VERSION ""

NS_ :

BS_:

BU_:

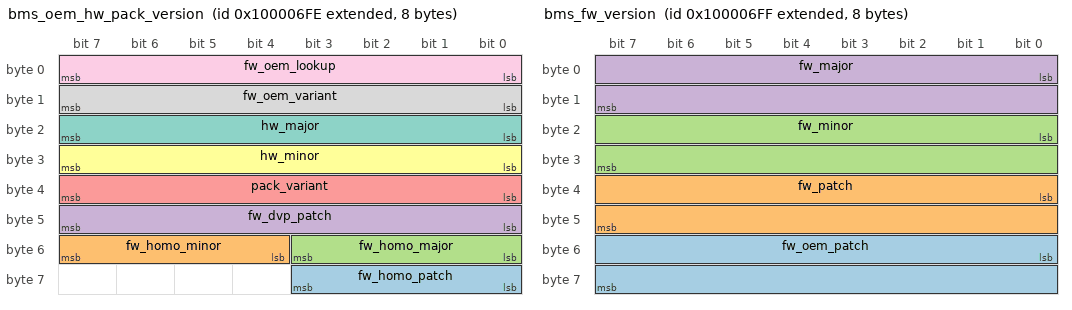
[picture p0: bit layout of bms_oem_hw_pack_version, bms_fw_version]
BO_ 2415920894 bms_oem_hw_pack_version: 8 Vector__XXX
 SG_ fw_homo_patch : 56|4@1+ (1,0) [0|15] "" Vector__XXX
 SG_ fw_homo_minor : 52|4@1+ (1,0) [0|15] "" Vector__XXX
 SG_ fw_homo_major : 48|4@1+ (1,0) [0|15] "" Vector__XXX
 SG_ fw_dvp_patch : 40|8@1+ (1,0) [0|255] "" Vector__XXX
 SG_ pack_variant : 32|8@1+ (1,0) [0|255] "" Vector__XXX
 SG_ hw_minor : 24|8@1+ (1,0) [0|255] "" Vector__XXX
 SG_ hw_major : 16|8@1+ (1,0) [0|255] "" Vector__XXX
 SG_ fw_oem_variant : 8|8@1+ (1,0) [0|255] "" Vector__XXX
 SG_ fw_oem_lookup : 0|8@1+ (1,0) [0|255] "" Vector__XXX

BO_ 2415920895 bms_fw_version: 8 Vector__XXX
 SG_ fw_oem_patch : 48|16@1+ (1,0) [0|65535] "" Vector__XXX
 SG_ fw_patch : 32|16@1+ (1,0) [0|65535] "" Vector__XXX
 SG_ fw_minor : 16|16@1+ (1,0) [0|65535] "" Vector__XXX
 SG_ fw_major : 0|16@1+ (1,0) [0|65535] "" Vector__XXX

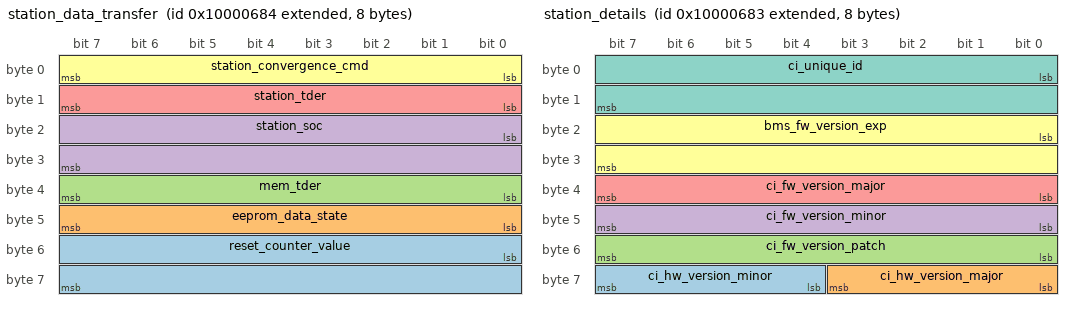
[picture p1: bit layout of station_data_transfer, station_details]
BO_ 2415920772 station_data_transfer: 8 Vector__XXX
 SG_ reset_counter_value : 48|16@1+ (1,0) [0|65535] "" Vector__XXX
 SG_ eeprom_data_state : 40|8@1+ (1,0) [0|255] "" Vector__XXX
 SG_ mem_tder : 32|8@1+ (1,0) [0|255] "" Vector__XXX
 SG_ station_soc : 16|16@1+ (1,0.1) [0.1|65535.1] "" Vector__XXX
 SG_ station_tder : 8|8@1+ (1,0) [0|255] "" Vector__XXX
 SG_ station_convergence_cmd : 0|8@1+ (1,0) [0|255] "" Vector__XXX

BO_ 2415920771 station_details: 8 Vector__XXX
 SG_ ci_hw_version_minor : 60|4@1+ (1,0) [0|15] "" Vector__XXX
 SG_ ci_hw_version_major : 56|4@1+ (1,0) [0|15] "" Vector__XXX
 SG_ ci_fw_version_patch : 48|8@1+ (1,0) [0|255] "" Vector__XXX
 SG_ ci_fw_version_minor : 40|8@1+ (1,0) [0|255] "" Vector__XXX
 SG_ ci_fw_version_major : 32|8@1+ (1,0) [0|255] "" Vector__XXX
 SG_ bms_fw_version_exp : 16|16@1+ (1,0) [0|65535] "" Vector__XXX
 SG_ ci_unique_id : 0|16@1+ (1,0) [0|65535] "" Vector__XXX

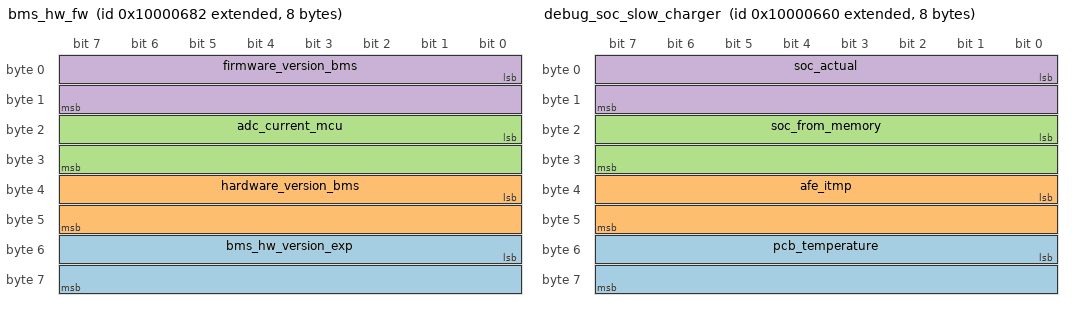
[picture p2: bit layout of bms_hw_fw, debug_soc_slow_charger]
BO_ 2415920770 bms_hw_fw: 8 Vector__XXX
 SG_ bms_hw_version_exp : 48|16@1+ (1,0) [0|65535] "" Vector__XXX
 SG_ hardware_version_bms : 32|16@1+ (1,0) [0|65535] "" Vector__XXX
 SG_ adc_current_mcu : 16|16@1+ (1,0) [0|65535] "" Vector__XXX
 SG_ firmware_version_bms : 0|16@1+ (1,0) [0|65535] "" Vector__XXX

BO_ 2415920769 bms_unique_Key: 8 Vector__XXX
 SG_ bms_unique_key : 0|64@1+ (1,0) [0|18446744073709551615] "" Vector__XXX

BO_ 2415920736 debug_soc_slow_charger: 8 Vector__XXX
 SG_ pcb_temperature : 48|16@1+ (0.01,-100.0) [-100.0|555.35] "" Vector__XXX
 SG_ afe_itmp : 32|16@1+ (0.01,-100.0) [-100.0|555.35] "" Vector__XXX
 SG_ soc_from_memory : 16|16@1+ (1,0) [0|65535] "" Vector__XXX
 SG_ soc_actual : 0|16@1+ (0.01,0.0) [0.0|655.35] "" Vector__XXX

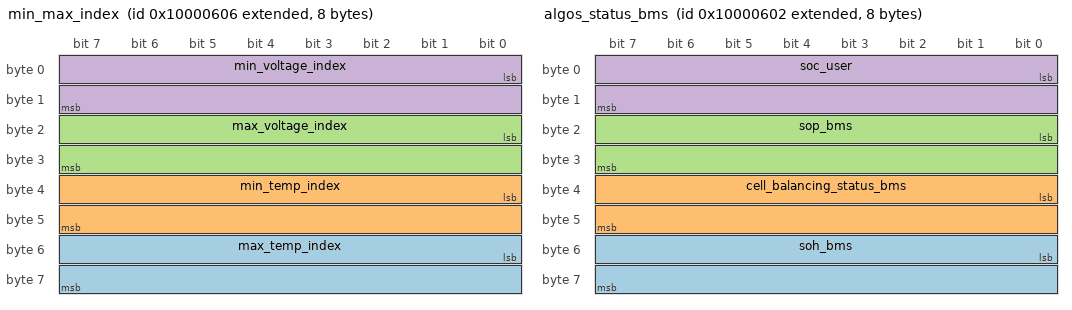
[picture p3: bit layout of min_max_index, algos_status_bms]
BO_ 2415920646 min_max_index: 8 Vector__XXX
 SG_ max_temp_index : 48|16@1+ (1,0) [0|65535] "" Vector__XXX
 SG_ min_temp_index : 32|16@1+ (1,0) [0|65535] "" Vector__XXX
 SG_ max_voltage_index : 16|16@1+ (1,0) [0|65535] "" Vector__XXX
 SG_ min_voltage_index : 0|16@1+ (1,0) [0|65535] "" Vector__XXX

BO_ 2415920647 history_of_protections: 8 Vector__XXX
 SG_ reset_cause : 48|16@1+ (1,0) [0|65535] "" Vector__XXX
 SG_ characterization_cycle_count : 32|16@1+ (0.1,0.0) [0.0|6553.5] "" Vector__XXX
 SG_ idp_bms_hist : 25|1@1+ (1,0) [0|1] "" Vector__XXX
 SG_ rm_bms_hist : 24|1@1+ (1,0) [0|1] "" Vector__XXX
 SG_ doc1_bms_hist : 23|1@1+ (1,0) [0|1] "" Vector__XXX
 SG_ cnot_bms_hist : 22|1@1+ (1,0) [0|1] "" Vector__XXX
 SG_ afe_tp_bms_hist : 21|1@1+ (1,0) [0|1] "" Vector__XXX
 SG_ ib1_bms_hist : 20|1@1+ (1,0) [0|1] "" Vector__XXX
 SG_ ccov_bms_hist : 19|1@1+ (1,0) [0|1] "" Vector__XXX
 SG_ sc_coc1_bms_hist : 18|1@1+ (1,0) [0|1] "" Vector__XXX
 SG_ ccuv_bms_hist : 17|1@1+ (1,0) [0|1] "" Vector__XXX
 SG_ icp_hist : 16|1@1+ (1,0) [0|1] "" Vector__XXX
 SG_ sc_coc_bms_hist : 15|1@1+ (1,0) [0|1] "" Vector__XXX
 SG_ roc_bms_hist : 14|1@1+ (1,0) [0|1] "" Vector__XXX
 SG_ scf_bms_hist : 13|1@1+ (1,0) [0|1] "" Vector__XXX
 SG_ tso_bms_hist : 12|1@1+ (1,0) [0|1] "" Vector__XXX
 SG_ ib_bms_hist : 11|1@1+ (1,0) [0|1] "" Vector__XXX
 SG_ cso_bms_hist : 10|1@1+ (1,0) [0|1] "" Vector__XXX
 SG_ dut_bms_hist : 9|1@1+ (1,0) [0|1] "" Vector__XXX
 SG_ cut_bms_hist : 8|1@1+ (1,0) [0|1] "" Vector__XXX
 SG_ dot_bms_hist : 7|1@1+ (1,0) [0|1] "" Vector__XXX
 SG_ cot_bms_hist : 6|1@1+ (1,0) [0|1] "" Vector__XXX
 SG_ doc_bms_hist : 5|1@1+ (1,0) [0|1] "" Vector__XXX
 SG_ coc_bms_hist : 4|1@1+ (1,0) [0|1] "" Vector__XXX
 SG_ puv_bms_hist : 3|1@1+ (1,0) [0|1] "" Vector__XXX
 SG_ pov_bms_hist : 2|1@1+ (1,0) [0|1] "" Vector__XXX
 SG_ cuv_bms_hist : 1|1@1+ (1,0) [0|1] "" Vector__XXX
 SG_ cov_bms_hist : 0|1@1+ (1,0) [0|1] "" Vector__XXX

BO_ 2415920768 battery_unique_key: 8 Vector__XXX
 SG_ battery_unique_key : 0|64@1+ (1,0) [0|18446744073709551615] "" Vector__XXX

BO_ 2415920642 algos_status_bms: 8 Vector__XXX
 SG_ soh_bms : 48|16@1+ (0.01,0.0) [0.0|655.35] "" Vector__XXX
 SG_ cell_balancing_status_bms : 32|16@1+ (1,0) [0|65535] "" Vector__XXX
 SG_ sop_bms : 16|16@1+ (1,0) [0|65535] "" Vector__XXX
 SG_ soc_user : 0|16@1+ (0.01,0.0) [0.0|655.35] "" Vector__XXX

BO_ 2415920641 safety_status_bms: 8 Vector__XXX
 SG_ idp_flag_bms : 57|1@1+ (1,0) [0|1] "" Vector__XXX
 SG_ rm_flag_bms : 56|1@1+ (1,0) [0|1] "" Vector__XXX
 SG_ doc1_flag_bms : 55|1@1+ (1,0) [0|1] "" Vector__XXX
 SG_ cnot_flag_bms : 54|1@1+ (1,0) [0|1] "" Vector__XXX
 SG_ afe_tp_bms_flag : 53|1@1+ (1,0) [0|1] "" Vector__XXX
 SG_ ib1_bms_flag : 52|1@1+ (1,0) [0|1] "" Vector__XXX
 SG_ ccov_flag_bms : 51|1@1+ (1,0) [0|1] "" Vector__XXX
 SG_ sc_coc1_flag_bms : 50|1@1+ (1,0) [0|1] "" Vector__XXX
 SG_ ccuv_flag_bms : 49|1@1+ (1,0) [0|1] "" Vector__XXX
 SG_ icp_flag : 48|1@1+ (1,0) [0|1] "" Vector__XXX
 SG_ sc_coc_flag_bms : 47|1@1+ (1,0) [0|1] "" Vector__XXX
 SG_ roc_flag_bms : 46|1@1+ (1,0) [0|1] "" Vector__XXX
 SG_ scf_flag_bms : 45|1@1+ (1,0) [0|1] "" Vector__XXX
 SG_ tso_flag_bms : 44|1@1+ (1,0) [0|1] "" Vector__XXX
 SG_ ib_bms_flag : 43|1@1+ (1,0) [0|1] "" Vector__XXX
 SG_ cso_flag_bms : 42|1@1+ (1,0) [0|1] "" Vector__XXX
 SG_ dut_flag_bms : 41|1@1+ (1,0) [0|1] "" Vector__XXX
 SG_ cut_flag_bms : 40|1@1+ (1,0) [0|1] "" Vector__XXX
 SG_ dot_flag_bms : 39|1@1+ (1,0) [0|1] "" Vector__XXX
 SG_ cot_flag_bms : 38|1@1+ (1,0) [0|1] "" Vector__XXX
 SG_ doc_flag_bms : 37|1@1+ (1,0) [0|1] "" Vector__XXX
 SG_ coc_flag_bms : 36|1@1+ (1,0) [0|1] "" Vector__XXX
 SG_ puv_flag_bms : 35|1@1+ (1,0) [0|1] "" Vector__XXX
 SG_ pov_flag_bms : 34|1@1+ (1,0) [0|1] "" Vector__XXX
 SG_ cuv_flag_bms : 33|1@1+ (1,0) [0|1] "" Vector__XXX
 SG_ cov_flag_bms : 32|1@1+ (1,0) [0|1] "" Vector__XXX
 SG_ idp_bms : 25|1@1+ (1,0) [0|1] "" Vector__XXX
 SG_ rm_bms : 24|1@1+ (1,0) [0|1] "" Vector__XXX
 SG_ doc1_bms : 23|1@1+ (1,0) [0|1] "" Vector__XXX
 SG_ cnot_bms : 22|1@1+ (1,0) [0|1] "" Vector__XXX
 SG_ afe_tp_bms : 21|1@1+ (1,0) [0|1] "" Vector__XXX
 SG_ ib1_bms : 20|1@1+ (1,0) [0|1] "" Vector__XXX
 SG_ ccov_bms : 19|1@1+ (1,0) [0|1] "" Vector__XXX
 SG_ sc_coc1_bms : 18|1@1+ (1,0) [0|1] "" Vector__XXX
 SG_ ccuv_bms : 17|1@1+ (1,0) [0|1] "" Vector__XXX
 SG_ icp_status : 16|1@1+ (1,0) [0|1] "" Vector__XXX
 SG_ sc_coc_bms : 15|1@1+ (1,0) [0|1] "" Vector__XXX
 SG_ roc_bms : 14|1@1+ (1,0) [0|1] "" Vector__XXX
 SG_ scf_bms : 13|1@1+ (1,0) [0|1] "" Vector__XXX
 SG_ tso_bms : 12|1@1+ (1,0) [0|1] "" Vector__XXX
 SG_ ib_bms : 11|1@1+ (1,0) [0|1] "" Vector__XXX
 SG_ cso_bms : 10|1@1+ (1,0) [0|1] "" Vector__XXX
 SG_ dut_bms : 9|1@1+ (1,0) [0|1] "" Vector__XXX
 SG_ cut_bms : 8|1@1+ (1,0) [0|1] "" Vector__XXX
 SG_ dot_bms : 7|1@1+ (1,0) [0|1] "" Vector__XXX
 SG_ cot_bms : 6|1@1+ (1,0) [0|1] "" Vector__XXX
 SG_ doc_bms : 5|1@1+ (1,0) [0|1] "" Vector__XXX
 SG_ coc_bms : 4|1@1+ (1,0) [0|1] "" Vector__XXX
 SG_ puv_bms : 3|1@1+ (1,0) [0|1] "" Vector__XXX
 SG_ pov_bms : 2|1@1+ (1,0) [0|1] "" Vector__XXX
 SG_ cuv_bms : 1|1@1+ (1,0) [0|1] "" Vector__XXX
 SG_ cov_bms : 0|1@1+ (1,0) [0|1] "" Vector__XXX

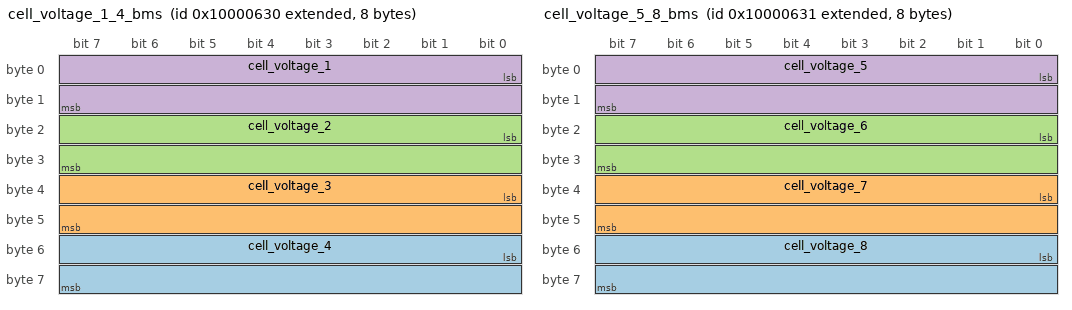
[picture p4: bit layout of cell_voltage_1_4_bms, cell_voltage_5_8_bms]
BO_ 2415920688 cell_voltage_1_4_bms: 8 Vector__XXX
 SG_ cell_voltage_4 : 48|16@1+ (0.0001,0.0) [0.0|6.5535000000000005] "" Vector__XXX
 SG_ cell_voltage_3 : 32|16@1+ (0.0001,0.0) [0.0|6.5535000000000005] "" Vector__XXX
 SG_ cell_voltage_2 : 16|16@1+ (0.0001,0.0) [0.0|6.5535000000000005] "" Vector__XXX
 SG_ cell_voltage_1 : 0|16@1+ (0.0001,0.0) [0.0|6.5535000000000005] "" Vector__XXX

BO_ 2415920689 cell_voltage_5_8_bms: 8 Vector__XXX
 SG_ cell_voltage_8 : 48|16@1+ (0.0001,0.0) [0.0|6.5535000000000005] "" Vector__XXX
 SG_ cell_voltage_7 : 32|16@1+ (0.0001,0.0) [0.0|6.5535000000000005] "" Vector__XXX
 SG_ cell_voltage_6 : 16|16@1+ (0.0001,0.0) [0.0|6.5535000000000005] "" Vector__XXX
 SG_ cell_voltage_5 : 0|16@1+ (0.0001,0.0) [0.0|6.5535000000000005] "" Vector__XXX

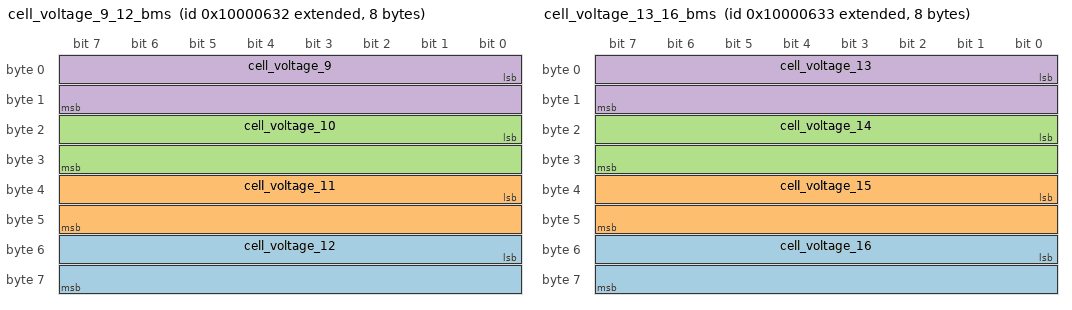
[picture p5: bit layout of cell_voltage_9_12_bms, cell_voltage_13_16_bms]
BO_ 2415920690 cell_voltage_9_12_bms: 8 Vector__XXX
 SG_ cell_voltage_12 : 48|16@1+ (0.0001,0.0) [0.0|6.5535000000000005] "" Vector__XXX
 SG_ cell_voltage_11 : 32|16@1+ (0.0001,0.0) [0.0|6.5535000000000005] "" Vector__XXX
 SG_ cell_voltage_10 : 16|16@1+ (0.0001,0.0) [0.0|6.5535000000000005] "" Vector__XXX
 SG_ cell_voltage_9 : 0|16@1+ (0.0001,0.0) [0.0|6.5535000000000005] "" Vector__XXX

BO_ 2415920691 cell_voltage_13_16_bms: 8 Vector__XXX
 SG_ cell_voltage_16 : 48|16@1+ (0.0001,0.0) [0.0|6.5535000000000005] "" Vector__XXX
 SG_ cell_voltage_15 : 32|16@1+ (0.0001,0.0) [0.0|6.5535000000000005] "" Vector__XXX
 SG_ cell_voltage_14 : 16|16@1+ (0.0001,0.0) [0.0|6.5535000000000005] "" Vector__XXX
 SG_ cell_voltage_13 : 0|16@1+ (0.0001,0.0) [0.0|6.5535000000000005] "" Vector__XXX

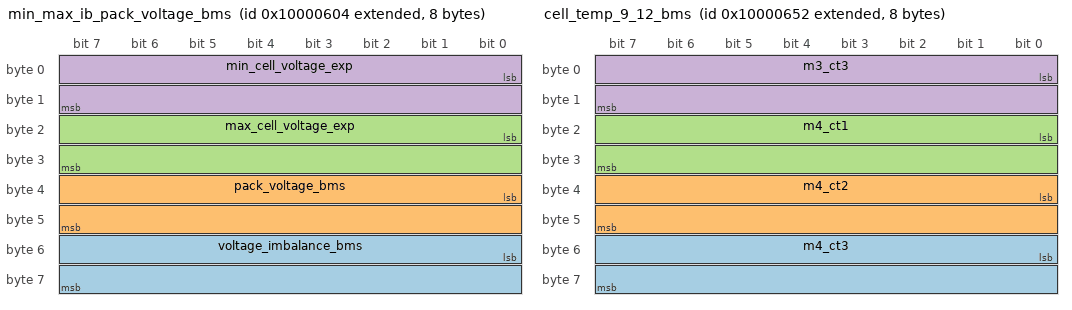
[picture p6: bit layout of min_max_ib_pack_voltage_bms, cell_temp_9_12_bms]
BO_ 2415920644 min_max_ib_pack_voltage_bms: 8 Vector__XXX
 SG_ voltage_imbalance_bms : 48|16@1+ (0.0001,0.0) [0.0|6.5535000000000005] "" Vector__XXX
 SG_ pack_voltage_bms : 32|16@1+ (0.01,0.0) [0.0|655.35] "" Vector__XXX
 SG_ max_cell_voltage_exp : 16|16@1+ (0.0001,0.0) [0.0|6.5535000000000005] "" Vector__XXX
 SG_ min_cell_voltage_exp : 0|16@1+ (0.0001,0.0) [0.0|6.5535000000000005] "" Vector__XXX

BO_ 2415920722 cell_temp_9_12_bms: 8 Vector__XXX
 SG_ m4_ct3 : 48|16@1+ (0.01,-100.0) [-100.0|555.35] "" Vector__XXX
 SG_ m4_ct2 : 32|16@1+ (0.01,-100.0) [-100.0|555.35] "" Vector__XXX
 SG_ m4_ct1 : 16|16@1+ (0.01,-100.0) [-100.0|555.35] "" Vector__XXX
 SG_ m3_ct3 : 0|16@1+ (0.01,-100.0) [-100.0|555.35] "" Vector__XXX

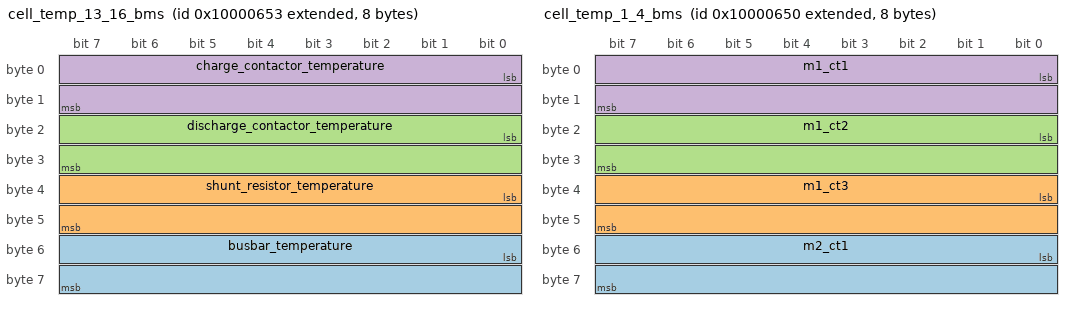
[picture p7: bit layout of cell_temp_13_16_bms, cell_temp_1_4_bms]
BO_ 2415920723 cell_temp_13_16_bms: 8 Vector__XXX
 SG_ busbar_temperature : 48|16@1+ (0.01,-100.0) [-100.0|555.35] "" Vector__XXX
 SG_ shunt_resistor_temperature : 32|16@1+ (0.01,-100.0) [-100.0|555.35] "" Vector__XXX
 SG_ discharge_contactor_temperature : 16|16@1+ (0.01,-100.0) [-100.0|555.35] "" Vector__XXX
 SG_ charge_contactor_temperature : 0|16@1+ (0.01,-100.0) [-100.0|555.35] "" Vector__XXX

BO_ 2415920720 cell_temp_1_4_bms: 8 Vector__XXX
 SG_ m2_ct1 : 48|16@1+ (0.01,-100.0) [-100.0|555.35] "" Vector__XXX
 SG_ m1_ct3 : 32|16@1+ (0.01,-100.0) [-100.0|555.35] "" Vector__XXX
 SG_ m1_ct2 : 16|16@1+ (0.01,-100.0) [-100.0|555.35] "" Vector__XXX
 SG_ m1_ct1 : 0|16@1+ (0.01,-100.0) [-100.0|555.35] "" Vector__XXX

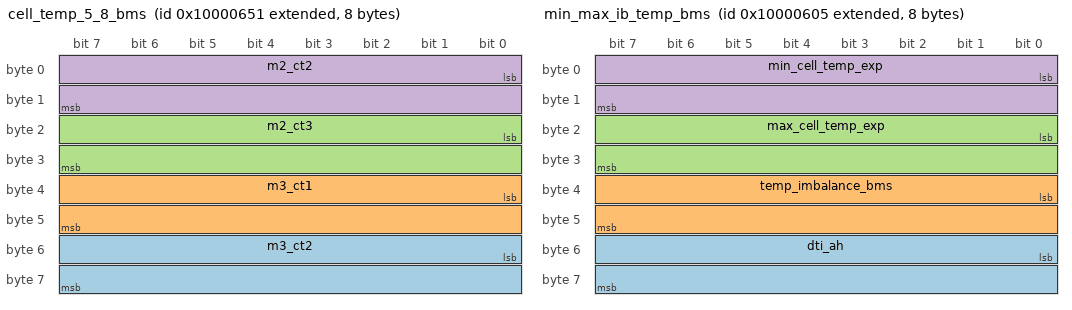
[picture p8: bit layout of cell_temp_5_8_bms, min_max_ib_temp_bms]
BO_ 2415920721 cell_temp_5_8_bms: 8 Vector__XXX
 SG_ m3_ct2 : 48|16@1+ (0.01,-100.0) [-100.0|555.35] "" Vector__XXX
 SG_ m3_ct1 : 32|16@1+ (0.01,-100.0) [-100.0|555.35] "" Vector__XXX
 SG_ m2_ct3 : 16|16@1+ (0.01,-100.0) [-100.0|555.35] "" Vector__XXX
 SG_ m2_ct2 : 0|16@1+ (0.01,-100.0) [-100.0|555.35] "" Vector__XXX

BO_ 2415920645 min_max_ib_temp_bms: 8 Vector__XXX
 SG_ dti_ah : 48|16@1+ (0.1,0.0) [0.0|6553.5] "" Vector__XXX
 SG_ temp_imbalance_bms : 32|16@1+ (0.01,-100.0) [-100.0|555.35] "" Vector__XXX
 SG_ max_cell_temp_exp : 16|16@1+ (0.01,-100.0) [-100.0|555.35] "" Vector__XXX
 SG_ min_cell_temp_exp : 0|16@1+ (0.01,-100.0) [-100.0|555.35] "" Vector__XXX

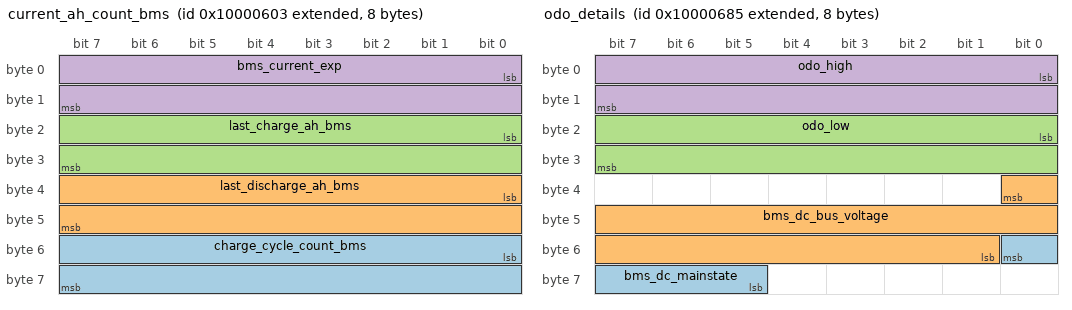
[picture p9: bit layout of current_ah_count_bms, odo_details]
BO_ 2415920643 current_ah_count_bms: 8 Vector__XXX
 SG_ charge_cycle_count_bms : 48|16@1+ (0.1,0.0) [0.0|6553.5] "" Vector__XXX
 SG_ last_discharge_ah_bms : 32|16@1+ (0.1,0.0) [0.0|6553.5] "" Vector__XXX
 SG_ last_charge_ah_bms : 16|16@1+ (0.1,0.0) [0.0|6553.5] "" Vector__XXX
 SG_ bms_current_exp : 0|16@1+ (0.1,-600.0) [-600.0|5953.5] "" Vector__XXX

BO_ 2415920640 sateflow_status_bms: 8 Vector__XXX
 SG_ gun_unlock_retry_count : 60|4@1+ (1,0) [0|15] "" Vector__XXX
 SG_ gun_lock_retry_count : 56|4@1+ (1,0) [0|15] "" Vector__XXX
 SG_ solenoid_feedback : 53|1@1+ (1,0) [0|1] "" Vector__XXX
 SG_ gun_lock_req : 52|1@1+ (1,0) [0|1] "" Vector__XXX
 SG_ gun_unlock_failed : 51|1@1+ (1,0) [0|1] "" Vector__XXX
 SG_ gun_unlock_status : 50|1@1+ (1,0) [0|1] "" Vector__XXX
 SG_ gun_lock_failed : 49|1@1+ (1,0) [0|1] "" Vector__XXX
 SG_ gun_lock_status : 48|1@1+ (1,0) [0|1] "" Vector__XXX
 SG_ cc_on_req : 39|1@1+ (1,0) [0|1] "" Vector__XXX
 SG_ motor_enable_out_bms : 38|1@1+ (1,0) [0|1] "" Vector__XXX
 SG_ discharge_contactor_out_bms : 37|1@1+ (1,0) [0|1] "" Vector__XXX
 SG_ discharge_precharge_out_bms : 36|1@1+ (1,0) [0|1] "" Vector__XXX
 SG_ charge_contactor_out_bms : 35|1@1+ (1,0) [0|1] "" Vector__XXX
 SG_ charge_precharge_out_bms : 34|1@1+ (1,0) [0|1] "" Vector__XXX
 SG_ proximity_pilot_in_bms : 33|1@1+ (1,0) [0|1] "" Vector__XXX
 SG_ key_in_bms : 32|1@1+ (1,0) [0|1] "" Vector__XXX
 SG_ shutdown_flag_3 : 26|1@1+ (1,0) [0|1] "" Vector__XXX
 SG_ shutdown_flag_2 : 25|1@1+ (1,0) [0|1] "" Vector__XXX
 SG_ shutdown_flag_1 : 24|1@1+ (1,0) [0|1] "" Vector__XXX
 SG_ battery_state_bms : 16|8@1+ (1,0) [0|255] "" Vector__XXX
 SG_ dut_warning : 14|1@1+ (1,0) [0|1] "" Vector__XXX
 SG_ tp_warning : 13|1@1+ (1,0) [0|1] "" Vector__XXX
 SG_ dot_warning : 12|1@1+ (1,0) [0|1] "" Vector__XXX
 SG_ tp_alarm_exp : 11|1@1+ (1,0) [0|1] "" Vector__XXX
 SG_ charge_complete_status : 10|1@1+ (1,0) [0|1] "" Vector__XXX
 SG_ fast_charger_detected_bms : 9|1@1+ (1,0) [0|1] "" Vector__XXX
 SG_ slow_charger_detected_bms : 8|1@1+ (1,0) [0|1] "" Vector__XXX
 SG_ discharge_path_status_bms : 7|1@1+ (1,0) [0|1] "" Vector__XXX
 SG_ charge_path_status_bms : 6|1@1+ (1,0) [0|1] "" Vector__XXX
 SG_ discharge_pf_ok_bms : 5|1@1+ (1,0) [0|1] "" Vector__XXX
 SG_ charge_pf_ok_bms : 4|1@1+ (1,0) [0|1] "" Vector__XXX
 SG_ discharge_io_ok_bms : 3|1@1+ (1,0) [0|1] "" Vector__XXX
 SG_ charge_io_ok_bms : 2|1@1+ (1,0) [0|1] "" Vector__XXX
 SG_ discharge_protection_ok_bms : 1|1@1+ (1,0) [0|1] "" Vector__XXX
 SG_ charge_protection_ok_bms : 0|1@1+ (1,0) [0|1] "" Vector__XXX

BO_ 2415920773 odo_details: 8 Vector__XXX
 SG_ bms_dc_mainstate : 48|4@0+ (1,0) [0|15] "" Vector__XXX
 SG_ bms_dc_bus_voltage : 32|16@0+ (0.01,0.0) [0.0|655.35] "" Vector__XXX
 SG_ odo_low : 16|16@1+ (1,0) [0|65535] "" Vector__XXX
 SG_ odo_high : 0|16@1+ (1,0) [0|65535] "" Vector__XXX

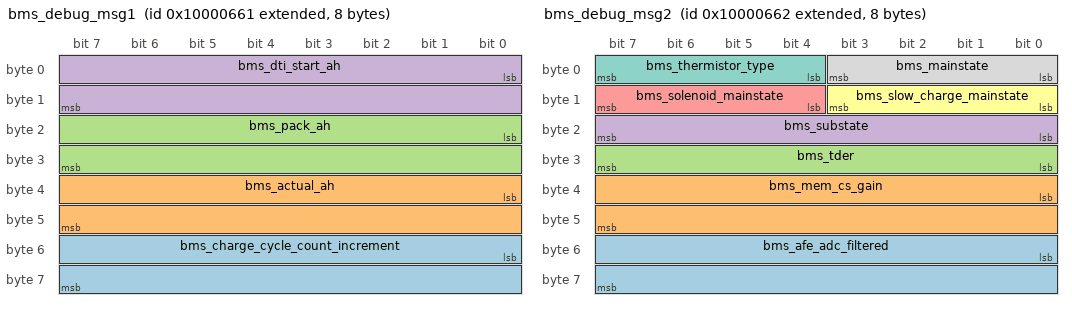
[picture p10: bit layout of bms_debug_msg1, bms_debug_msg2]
BO_ 2415920737 bms_debug_msg1: 8 Vector__XXX
 SG_ bms_charge_cycle_count_increment : 48|16@1+ (0.1,0.0) [0.0|6553.5] "" Vector__XXX
 SG_ bms_actual_ah : 32|16@1+ (0.1,0.0) [0.0|6553.5] "" Vector__XXX
 SG_ bms_pack_ah : 16|16@1+ (0.1,0.0) [0.0|6553.5] "" Vector__XXX
 SG_ bms_dti_start_ah : 0|16@1+ (0.1,0.0) [0.0|6553.5] "" Vector__XXX

BO_ 2415920738 bms_debug_msg2: 8 Vector__XXX
 SG_ bms_afe_adc_filtered : 48|16@1+ (1,0) [0|65535] "" Vector__XXX
 SG_ bms_mem_cs_gain : 32|16@1+ (1,0) [0|65535] "" Vector__XXX
 SG_ bms_tder : 24|8@1+ (1,0) [0|255] "" Vector__XXX
 SG_ bms_substate : 16|8@1+ (1,0) [0|255] "" Vector__XXX
 SG_ bms_solenoid_mainstate : 12|4@1+ (1,0) [0|15] "" Vector__XXX
 SG_ bms_slow_charge_mainstate : 8|4@1+ (1,0) [0|15] "" Vector__XXX
 SG_ bms_thermistor_type : 4|4@1+ (1,0) [0|15] "" Vector__XXX
 SG_ bms_mainstate : 0|4@1+ (1,0) [0|15] "" Vector__XXX

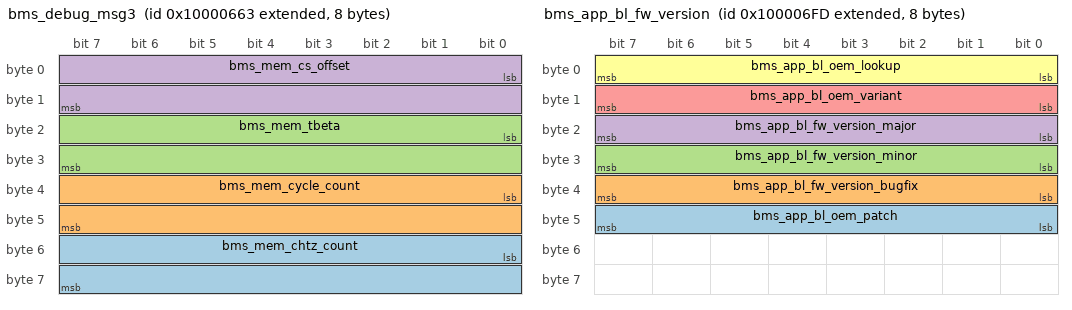
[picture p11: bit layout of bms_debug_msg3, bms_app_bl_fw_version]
BO_ 2415920739 bms_debug_msg3: 8 Vector__XXX
 SG_ bms_mem_chtz_count : 48|16@1+ (0.1,0.0) [0.0|6553.5] "" Vector__XXX
 SG_ bms_mem_cycle_count : 32|16@1+ (0.1,0.0) [0.0|6553.5] "" Vector__XXX
 SG_ bms_mem_tbeta : 16|16@1+ (1,0) [0|65535] "" Vector__XXX
 SG_ bms_mem_cs_offset : 0|16@1+ (1,0) [0|65535] "" Vector__XXX

BO_ 2415920893 bms_app_bl_fw_version: 8 Vector__XXX
 SG_ bms_app_bl_oem_patch : 40|8@1+ (1,0) [0|255] "" Vector__XXX
 SG_ bms_app_bl_fw_version_bugfix : 32|8@1+ (1,0) [0|255] "" Vector__XXX
 SG_ bms_app_bl_fw_version_minor : 24|8@1+ (1,0) [0|255] "" Vector__XXX
 SG_ bms_app_bl_fw_version_major : 16|8@1+ (1,0) [0|255] "" Vector__XXX
 SG_ bms_app_bl_oem_variant : 8|8@1+ (1,0) [0|255] "" Vector__XXX
 SG_ bms_app_bl_oem_lookup : 0|8@1+ (1,0) [0|255] "" Vector__XXX

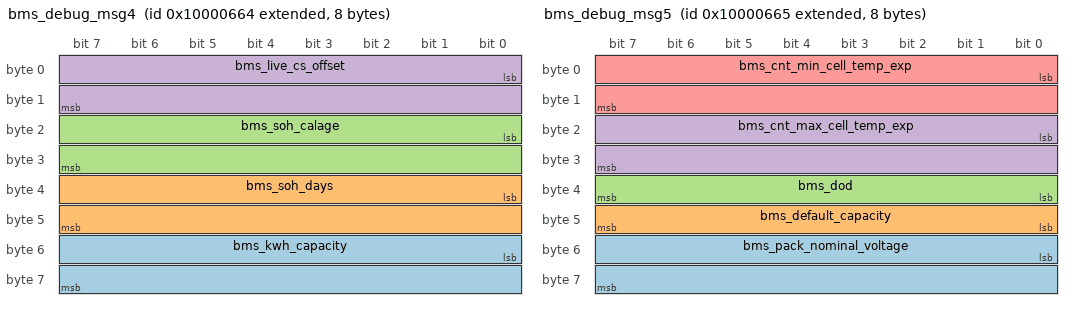
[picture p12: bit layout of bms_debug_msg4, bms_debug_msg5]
BO_ 2415920740 bms_debug_msg4: 8 Vector__XXX
 SG_ bms_kwh_capacity : 48|16@1+ (0.01,0.0) [0.0|655.35] "" Vector__XXX
 SG_ bms_soh_days : 32|16@1+ (1,0) [0|65535] "" Vector__XXX
 SG_ bms_soh_calage : 16|16@1+ (0.0001,0.0) [0.0|6.5535000000000005] "" Vector__XXX
 SG_ bms_live_cs_offset : 0|16@1+ (1,0) [0|65535] "" Vector__XXX

BO_ 2415920741 bms_debug_msg5: 8 Vector__XXX
 SG_ bms_pack_nominal_voltage : 48|16@1+ (0.1,0.0) [0.0|6553.5] "" Vector__XXX
 SG_ bms_default_capacity : 40|8@1+ (1,0) [0|255] "" Vector__XXX
 SG_ bms_dod : 32|8@1+ (1,0) [0|255] "" Vector__XXX
 SG_ bms_cnt_max_cell_temp_exp : 16|16@1+ (0.01,-100.0) [-100.0|555.35] "" Vector__XXX
 SG_ bms_cnt_min_cell_temp_exp : 0|16@1+ (0.01,-100.0) [-100.0|555.35] "" Vector__XXX

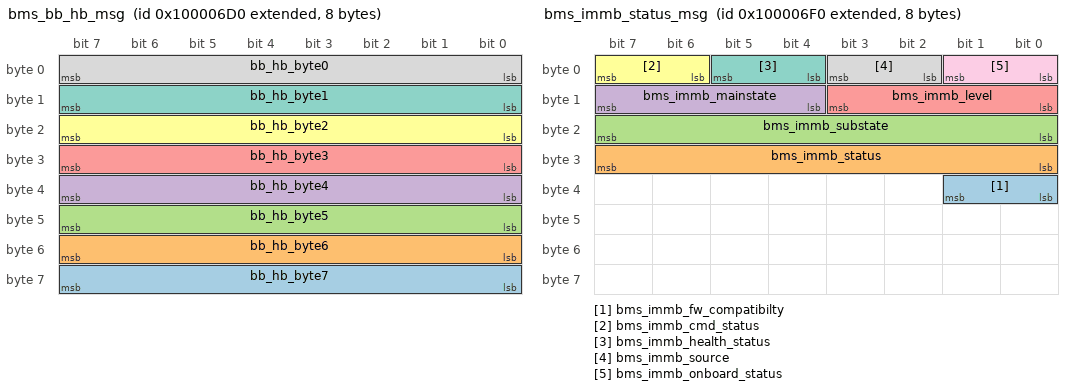
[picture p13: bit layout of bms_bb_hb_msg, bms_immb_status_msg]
BO_ 2415920848 bms_bb_hb_msg: 8 Vector__XXX
 SG_ bb_hb_byte7 : 56|8@1+ (1,0) [0|255] "" Vector__XXX
 SG_ bb_hb_byte6 : 48|8@1+ (1,0) [0|255] "" Vector__XXX
 SG_ bb_hb_byte5 : 40|8@1+ (1,0) [0|255] "" Vector__XXX
 SG_ bb_hb_byte4 : 32|8@1+ (1,0) [0|255] "" Vector__XXX
 SG_ bb_hb_byte3 : 24|8@1+ (1,0) [0|255] "" Vector__XXX
 SG_ bb_hb_byte2 : 16|8@1+ (1,0) [0|255] "" Vector__XXX
 SG_ bb_hb_byte1 : 8|8@1+ (1,0) [0|255] "" Vector__XXX
 SG_ bb_hb_byte0 : 0|8@1+ (1,0) [0|255] "" Vector__XXX

BO_ 2415920864 bms_immb_enable_msg: 8 Vector__XXX
 SG_ cloud_unique_id : 32|32@1+ (1,0) [0|4294967295] "" Vector__XXX
 SG_ cloud_special_level : 2|2@1+ (1,0) [0|3] "" Vector__XXX
 SG_ cloud_onboard_cmd : 0|2@1+ (1,0) [0|3] "" Vector__XXX

BO_ 2415920865 bms_immb_config_msg: 8 Vector__XXX
 SG_ cloud_immb_level : 4|4@1+ (1,0) [0|15] "" Vector__XXX
 SG_ cloud_immb_cmd : 0|2@1+ (1,0) [0|3] "" Vector__XXX

BO_ 2415920880 bms_immb_status_msg: 8 Vector__XXX
 SG_ bms_immb_fw_compatibilty : 32|2@1+ (1,0) [0|3] "" Vector__XXX
 SG_ bms_immb_status : 24|8@1+ (1,0) [0|255] "" Vector__XXX
 SG_ bms_immb_substate : 16|8@1+ (1,0) [0|255] "" Vector__XXX
 SG_ bms_immb_mainstate : 12|4@1+ (1,0) [0|15] "" Vector__XXX
 SG_ bms_immb_level : 8|4@1+ (1,0) [0|15] "" Vector__XXX
 SG_ bms_immb_cmd_status : 6|2@1+ (1,0) [0|3] "" Vector__XXX
 SG_ bms_immb_health_status : 4|2@1+ (1,0) [0|3] "" Vector__XXX
 SG_ bms_immb_source : 2|2@1+ (1,0) [0|3] "" Vector__XXX
 SG_ bms_immb_onboard_status : 0|2@1+ (1,0) [0|3] "" Vector__XXX

BO_ 518 ticm_msg16: 8 Vector__XXX
 SG_ sig_vtemp4 : 55|16@0+ (1,-40) [-40|65495] "" Vector__XXX
 SG_ sig_vtemp3 : 39|16@0+ (1,-40) [-40|65495] "" Vector__XXX
 SG_ sig_vtemp2 : 23|16@0+ (1,-40) [-40|65495] "" Vector__XXX
 SG_ sig_vtemp1 : 7|16@0+ (1,-40) [-40|65495] "" Vector__XXX

BO_ 546 ticm_msg15: 8 Vector__XXX
 SG_ sig_bms_fw_version : 7|16@0+ (1,0) [0|65535] "" Vector__XXX

BO_ 545 ticm_msg14: 8 Vector__XXX
 SG_ sig_bms_hw_version : 7|16@0+ (1,0) [0|65535] "" Vector__XXX

BO_ 526 ticm_msg13: 8 Vector__XXX
 SG_ sig_error_byte2 : 63|8@0+ (1,0) [0|255] "" Vector__XXX
 SG_ sig_error_byte1 : 55|8@0+ (1,0) [0|255] "" Vector__XXX
 SG_ sig_error_byte0 : 15|8@0+ (1,0) [0|255] "" Vector__XXX
 SG_ tp_alarm : 7|8@0+ (1,0) [0|255] "" Vector__XXX

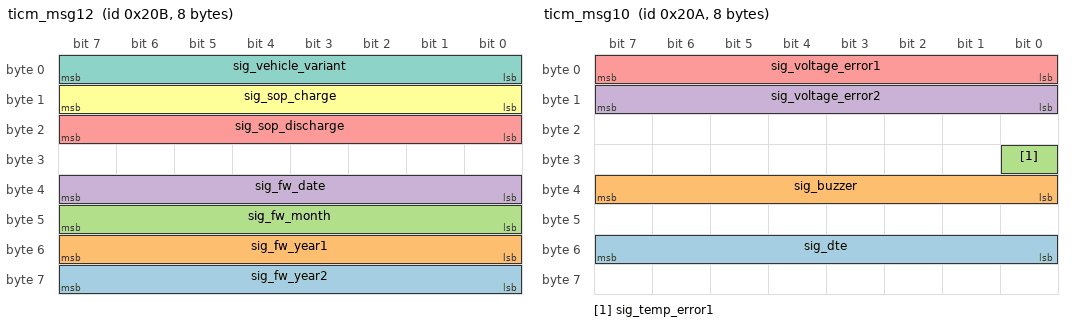
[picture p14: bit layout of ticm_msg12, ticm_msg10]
BO_ 523 ticm_msg12: 8 Vector__XXX
 SG_ sig_fw_year2 : 63|8@0+ (1,0) [0|255] "" Vector__XXX
 SG_ sig_fw_year1 : 55|8@0+ (1,0) [0|255] "" Vector__XXX
 SG_ sig_fw_month : 47|8@0+ (1,0) [0|255] "" Vector__XXX
 SG_ sig_fw_date : 39|8@0+ (1,0) [0|255] "" Vector__XXX
 SG_ sig_sop_discharge : 23|8@0+ (1,0) [0|255] "" Vector__XXX
 SG_ sig_sop_charge : 15|8@0+ (1,0) [0|255] "" Vector__XXX
 SG_ sig_vehicle_variant : 7|8@0+ (1,0) [0|255] "" Vector__XXX

BO_ 524 ticm_msg11: 8 Vector__XXX
 SG_ sig_energy_available : 55|16@0+ (1,0) [0|65535] "" Vector__XXX
 SG_ sig_available_capacity : 15|16@0+ (1,0) [0|65535] "" Vector__XXX
 SG_ sig_temp_error2 : 7|8@0+ (1,0) [0|255] "" Vector__XXX

BO_ 522 ticm_msg10: 8 Vector__XXX
 SG_ sig_dte : 55|8@0+ (1,0) [0|255] "" Vector__XXX
 SG_ sig_buzzer : 39|8@0+ (1,0) [0|255] "" Vector__XXX
 SG_ sig_temp_error1 : 24|1@0+ (1,0) [0|1] "" Vector__XXX
 SG_ sig_voltage_error2 : 15|8@0+ (1,0) [0|255] "" Vector__XXX
 SG_ sig_voltage_error1 : 7|8@0+ (1,0) [0|255] "" Vector__XXX

BO_ 531 ticm_msg9: 8 Vector__XXX
 SG_ sig_vcell16 : 55|16@0+ (0.001,0.0) [0.0|65.535] "" Vector__XXX
 SG_ sig_vcell15 : 39|16@0+ (0.001,0.0) [0.0|65.535] "" Vector__XXX
 SG_ sig_vcell14 : 23|16@0+ (0.001,0.0) [0.0|65.535] "" Vector__XXX
 SG_ sig_vcell13 : 7|16@0+ (0.001,0.0) [0.0|65.535] "" Vector__XXX

BO_ 530 ticm_msg8: 8 Vector__XXX
 SG_ sig_vcell12 : 55|16@0+ (0.001,0.0) [0.0|65.535] "" Vector__XXX
 SG_ sig_vcell11 : 39|16@0+ (0.001,0.0) [0.0|65.535] "" Vector__XXX
 SG_ sig_vcell10 : 23|16@0+ (0.001,0.0) [0.0|65.535] "" Vector__XXX
 SG_ sig_vcell9 : 7|16@0+ (0.001,0.0) [0.0|65.535] "" Vector__XXX

BO_ 529 ticm_msg7: 8 Vector__XXX
 SG_ sig_vcell8 : 55|16@0+ (0.001,0.0) [0.0|65.535] "" Vector__XXX
 SG_ sig_vcell7 : 39|16@0+ (0.001,0.0) [0.0|65.535] "" Vector__XXX
 SG_ sig_vcell6 : 23|16@0+ (0.001,0.0) [0.0|65.535] "" Vector__XXX
 SG_ sig_vcell5 : 7|16@0+ (0.001,0.0) [0.0|65.535] "" Vector__XXX

BO_ 528 ticm_msg6: 8 Vector__XXX
 SG_ sig_vcell4 : 55|16@0+ (0.001,0.0) [0.0|65.535] "" Vector__XXX
 SG_ sig_vcell3 : 39|16@0+ (0.001,0.0) [0.0|65.535] "" Vector__XXX
 SG_ sig_vcell2 : 23|16@0+ (0.001,0.0) [0.0|65.535] "" Vector__XXX
 SG_ sig_vcell1 : 7|16@0+ (0.001,0.0) [0.0|65.535] "" Vector__XXX

BO_ 517 ticm_msg5: 8 Vector__XXX
 SG_ sig_vtemp6 : 55|16@0+ (1,-40) [-40|65495] "" Vector__XXX
 SG_ sig_avg_cell_temp : 39|16@0+ (1,-40) [-40|65495] "" Vector__XXX
 SG_ min_cell_temp_bms : 23|16@0+ (1,-40) [-40|65495] "" Vector__XXX
 SG_ max_cell_temp_bms : 7|16@0+ (1,-40) [-40|65495] "" Vector__XXX

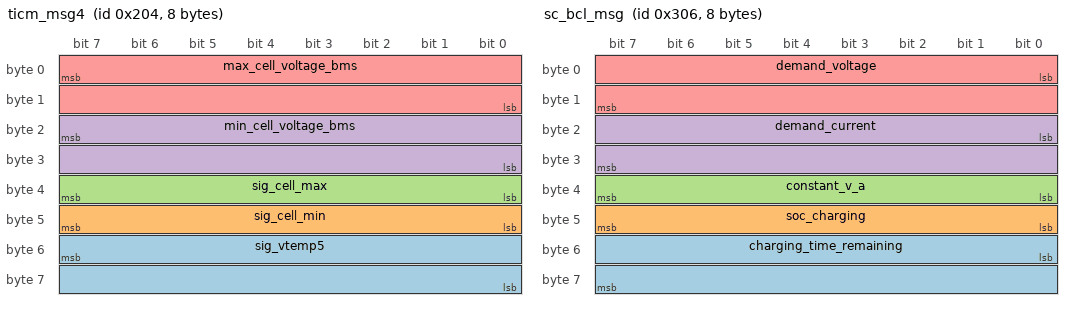
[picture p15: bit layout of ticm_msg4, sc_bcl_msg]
BO_ 516 ticm_msg4: 8 Vector__XXX
 SG_ sig_vtemp5 : 55|16@0+ (1,-40) [-40|65495] "" Vector__XXX
 SG_ sig_cell_min : 47|8@0+ (1,0) [0|255] "" Vector__XXX
 SG_ sig_cell_max : 39|8@0+ (1,0) [0|255] "" Vector__XXX
 SG_ min_cell_voltage_bms : 23|16@0+ (0.001,0.0) [0.0|65.535] "" Vector__XXX
 SG_ max_cell_voltage_bms : 7|16@0+ (0.001,0.0) [0.0|65.535] "" Vector__XXX

BO_ 515 ticm_msg3: 8 Vector__XXX
 SG_ sig_power_on_status : 31|8@0+ (1,0) [0|255] "" Vector__XXX
 SG_ sig_pack_status : 15|8@0- (1,0) [-128|127] "" Vector__XXX
 SG_ sig_fault_status : 7|8@0+ (1,0) [0|255] "" Vector__XXX

BO_ 514 ticm_msg2: 8 Vector__XXX
 SG_ sig_cycle_count : 39|16@0+ (1,0) [0|65535] "" Vector__XXX
 SG_ sig_soh : 7|16@0+ (1,0) [0|65535] "" Vector__XXX

BO_ 513 ticm_msg1: 8 Vector__XXX
 SG_ sig_total_battery_ah_capacity : 55|16@0+ (1,0) [0|65535] "" Vector__XXX
 SG_ sig_state_of_charge : 39|16@0+ (1,0) [0|65535] "" Vector__XXX
 SG_ battery_current : 23|16@0- (1,0) [-32768|32767] "" Vector__XXX
 SG_ battery_voltage : 7|16@0+ (0.001,0.0) [0.0|65.535] "" Vector__XXX

BO_ 1284 ticm_msg17: 8 Vector__XXX
 SG_ sig_drive_mode : 7|8@0+ (1,0) [0|255] "" Vector__XXX

BO_ 779 sc_cem_msg: 8 Vector__XXX
 SG_ charger_error_cause : 8|16@1+ (1,0) [0|65535] "" Vector__XXX
 SG_ charger_receive_timeout : 0|8@1+ (1,0) [0|255] "" Vector__XXX

BO_ 777 sc_cst_msg: 8 Vector__XXX
 SG_ bms_stop_charging_reason : 0|8@1+ (1,0) [0|255] "" Vector__XXX

BO_ 776 sc_bst_msg: 8 Vector__XXX
 SG_ charger_stop_reason : 0|8@1+ (1,0) [0|255] "" Vector__XXX

BO_ 775 sc_ccs_msg: 8 Vector__XXX
 SG_ charger_time_remaining : 32|8@1+ (1,0) [0|255] "" Vector__XXX
 SG_ fb_charger_current : 16|16@1+ (0.1,-40.0) [-40.0|6513.5] "" Vector__XXX
 SG_ fb_charger_voltage : 0|16@1+ (0.1,0.0) [0.0|6553.5] "" Vector__XXX

BO_ 774 sc_bcl_msg: 8 Vector__XXX
 SG_ charging_time_remaining : 48|16@1+ (1,0) [0|65535] "" Vector__XXX
 SG_ soc_charging : 40|8@1+ (1,0) [0|255] "" Vector__XXX
 SG_ constant_v_a : 32|8@1+ (1,0) [0|255] "" Vector__XXX
 SG_ demand_current : 16|16@1+ (0.1,-40.0) [-40.0|6513.5] "" Vector__XXX
 SG_ demand_voltage : 0|16@1+ (0.1,0.0) [0.0|6553.5] "" Vector__XXX

BO_ 773 sc_cro_msg: 8 Vector__XXX
 SG_ charger_ready : 0|8@1+ (1,0) [0|255] "" Vector__XXX

BO_ 772 sc_bro_msg: 8 Vector__XXX
 SG_ bms_ready_to_charge : 0|8@1+ (1,0) [0|255] "" Vector__XXX

BO_ 771 sc_cml_msg: 8 Vector__XXX
 SG_ charger_min_out_i : 48|16@1+ (0.1,-40.0) [-40.0|6513.5] "" Vector__XXX
 SG_ charger_max_out_i : 32|16@1+ (0.1,-40.0) [-40.0|6513.5] "" Vector__XXX
 SG_ charger_min_out_v : 16|16@1+ (0.1,0.0) [0.0|6553.5] "" Vector__XXX
 SG_ charger_max_out_v : 0|16@1+ (0.1,0.0) [0.0|6553.5] "" Vector__XXX

BO_ 770 sc_bhm_msg: 8 Vector__XXX
 SG_ bms_fw_bug_fix_version : 16|8@1+ (1,0) [0|255] "" Vector__XXX
 SG_ bms_fw_minor_version : 8|8@1+ (1,0) [0|255] "" Vector__XXX
 SG_ bms_fw_major_version : 0|8@1+ (1,0) [0|255] "" Vector__XXX

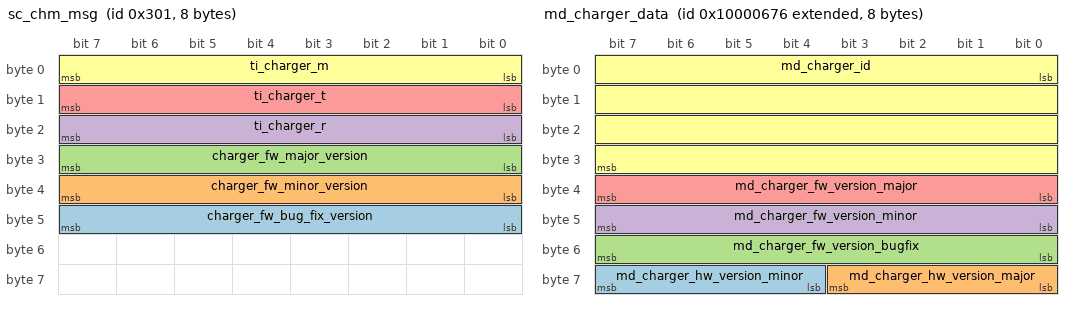
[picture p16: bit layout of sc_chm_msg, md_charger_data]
BO_ 769 sc_chm_msg: 8 Vector__XXX
 SG_ charger_fw_bug_fix_version : 40|8@1+ (1,0) [0|255] "" Vector__XXX
 SG_ charger_fw_minor_version : 32|8@1+ (1,0) [0|255] "" Vector__XXX
 SG_ charger_fw_major_version : 24|8@1+ (1,0) [0|255] "" Vector__XXX
 SG_ ti_charger_r : 16|8@1+ (1,0) [0|255] "" Vector__XXX
 SG_ ti_charger_t : 8|8@1+ (1,0) [0|255] "" Vector__XXX
 SG_ ti_charger_m : 0|8@1+ (1,0) [0|255] "" Vector__XXX

BO_ 2415920755 md_bms_fw_version: 8 Vector__XXX
 SG_ md_bms_oem_patch : 48|16@1+ (1,0) [0|65535] "" Vector__XXX
 SG_ md_bms_fw_patch : 32|16@1+ (1,0) [0|65535] "" Vector__XXX
 SG_ md_bms_fw_minor : 16|16@1+ (1,0) [0|65535] "" Vector__XXX
 SG_ md_bms_fw_major : 0|16@1+ (1,0) [0|65535] "" Vector__XXX

BO_ 2415920758 md_charger_data: 8 Vector__XXX
 SG_ md_charger_hw_version_minor : 60|4@1+ (1,0) [0|15] "" Vector__XXX
 SG_ md_charger_hw_version_major : 56|4@1+ (1,0) [0|15] "" Vector__XXX
 SG_ md_charger_fw_version_bugfix : 48|8@1+ (1,0) [0|255] "" Vector__XXX
 SG_ md_charger_fw_version_minor : 40|8@1+ (1,0) [0|255] "" Vector__XXX
 SG_ md_charger_fw_version_major : 32|8@1+ (1,0) [0|255] "" Vector__XXX
 SG_ md_charger_id : 0|32@1+ (1,0) [0|4294967295] "" Vector__XXX

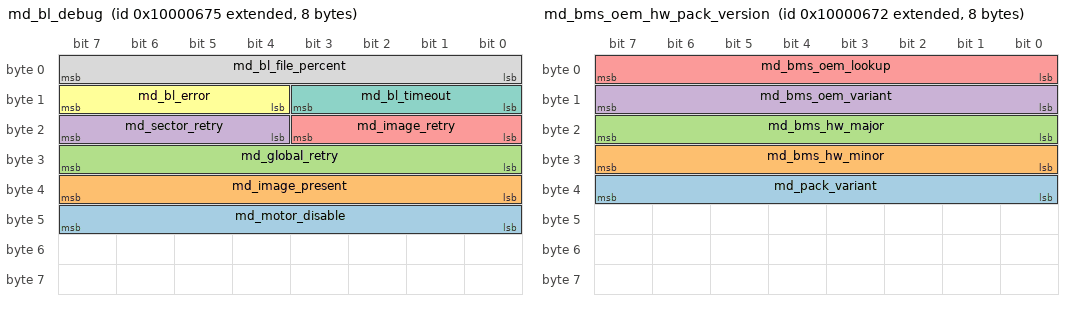
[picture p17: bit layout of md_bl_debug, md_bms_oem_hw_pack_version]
BO_ 2415920757 md_bl_debug: 8 Vector__XXX
 SG_ md_motor_disable : 40|8@1+ (1,0) [0|255] "" Vector__XXX
 SG_ md_image_present : 32|8@1+ (1,0) [0|255] "" Vector__XXX
 SG_ md_global_retry : 24|8@1+ (1,0) [0|255] "" Vector__XXX
 SG_ md_sector_retry : 20|4@1+ (1,0) [0|15] "" Vector__XXX
 SG_ md_image_retry : 16|4@1+ (1,0) [0|15] "" Vector__XXX
 SG_ md_bl_error : 12|4@1+ (1,0) [0|15] "" Vector__XXX
 SG_ md_bl_timeout : 8|4@1+ (1,0) [0|15] "" Vector__XXX
 SG_ md_bl_file_percent : 0|8@1+ (1,0) [0|255] "" Vector__XXX

BO_ 2415920756 md_soc_cycle_count: 8 Vector__XXX
 SG_ md_cycle_count : 8|16@1+ (1,0) [0|65535] "" Vector__XXX
 SG_ md_soc : 0|8@1+ (1,0) [0|255] "" Vector__XXX

BO_ 2415920754 md_bms_oem_hw_pack_version: 8 Vector__XXX
 SG_ md_pack_variant : 32|8@1+ (1,0) [0|255] "" Vector__XXX
 SG_ md_bms_hw_minor : 24|8@1+ (1,0) [0|255] "" Vector__XXX
 SG_ md_bms_hw_major : 16|8@1+ (1,0) [0|255] "" Vector__XXX
 SG_ md_bms_oem_variant : 8|8@1+ (1,0) [0|255] "" Vector__XXX
 SG_ md_bms_oem_lookup : 0|8@1+ (1,0) [0|255] "" Vector__XXX

BO_ 2415920753 md_battery_unique_key: 8 Vector__XXX
 SG_ md_battery_unique_key : 0|64@1+ (1,0) [0|18446744073709551615] "" Vector__XXX

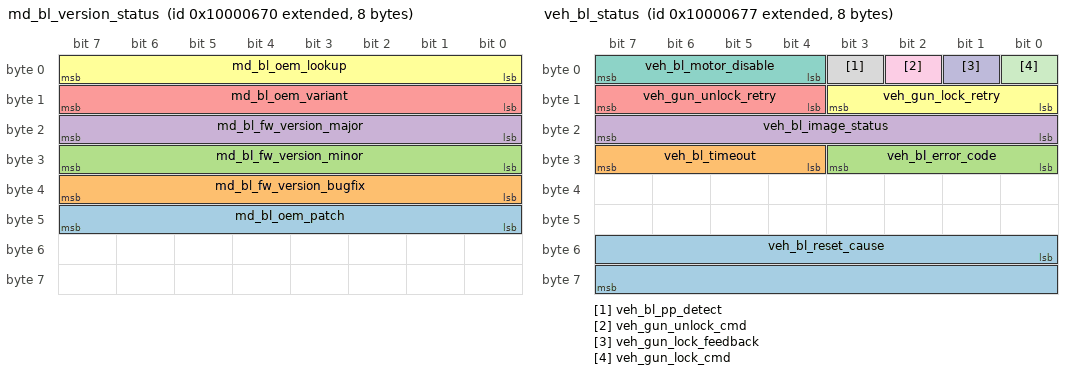
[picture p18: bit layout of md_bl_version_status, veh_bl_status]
BO_ 2415920752 md_bl_version_status: 8 Vector__XXX
 SG_ md_bl_oem_patch : 40|8@1+ (1,0) [0|255] "" Vector__XXX
 SG_ md_bl_fw_version_bugfix : 32|8@1+ (1,0) [0|255] "" Vector__XXX
 SG_ md_bl_fw_version_minor : 24|8@1+ (1,0) [0|255] "" Vector__XXX
 SG_ md_bl_fw_version_major : 16|8@1+ (1,0) [0|255] "" Vector__XXX
 SG_ md_bl_oem_variant : 8|8@1+ (1,0) [0|255] "" Vector__XXX
 SG_ md_bl_oem_lookup : 0|8@1+ (1,0) [0|255] "" Vector__XXX

BO_ 2415920759 veh_bl_status: 8 Vector__XXX
 SG_ veh_bl_reset_cause : 48|16@1+ (1,0) [0|65535] "" Vector__XXX
 SG_ veh_bl_timeout : 28|4@1+ (1,0) [0|15] "" Vector__XXX
 SG_ veh_bl_error_code : 24|4@1+ (1,0) [0|15] "" Vector__XXX
 SG_ veh_bl_image_status : 16|8@1+ (1,0) [0|255] "" Vector__XXX
 SG_ veh_gun_unlock_retry : 12|4@1+ (1,0) [0|15] "" Vector__XXX
 SG_ veh_gun_lock_retry : 8|4@1+ (1,0) [0|15] "" Vector__XXX
 SG_ veh_bl_motor_disable : 4|4@1+ (1,0) [0|15] "" Vector__XXX
 SG_ veh_bl_pp_detect : 3|1@1+ (1,0) [0|1] "" Vector__XXX
 SG_ veh_gun_unlock_cmd : 2|1@1+ (1,0) [0|1] "" Vector__XXX
 SG_ veh_gun_lock_feedback : 1|1@1+ (1,0) [0|1] "" Vector__XXX
 SG_ veh_gun_lock_cmd : 0|1@1+ (1,0) [0|1] "" Vector__XXX

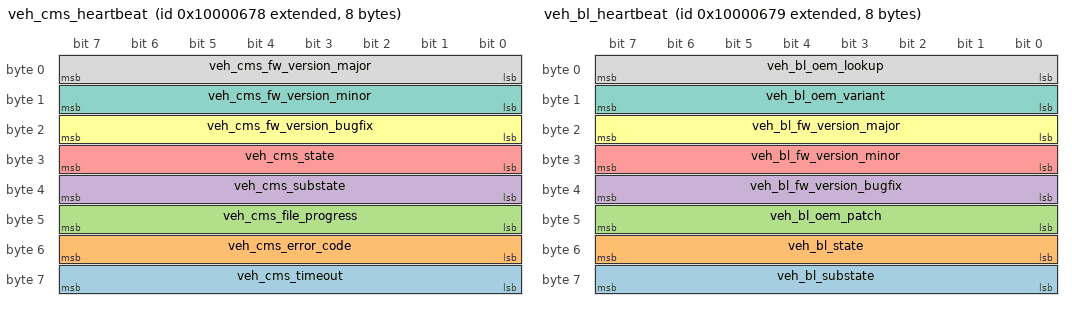
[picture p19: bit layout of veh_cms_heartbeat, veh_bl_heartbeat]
BO_ 2415920760 veh_cms_heartbeat: 8 Vector__XXX
 SG_ veh_cms_timeout : 56|8@1+ (1,0) [0|255] "" Vector__XXX
 SG_ veh_cms_error_code : 48|8@1+ (1,0) [0|255] "" Vector__XXX
 SG_ veh_cms_file_progress : 40|8@1+ (1,0) [0|255] "" Vector__XXX
 SG_ veh_cms_substate : 32|8@1+ (1,0) [0|255] "" Vector__XXX
 SG_ veh_cms_state : 24|8@1+ (1,0) [0|255] "" Vector__XXX
 SG_ veh_cms_fw_version_bugfix : 16|8@1+ (1,0) [0|255] "" Vector__XXX
 SG_ veh_cms_fw_version_minor : 8|8@1+ (1,0) [0|255] "" Vector__XXX
 SG_ veh_cms_fw_version_major : 0|8@1+ (1,0) [0|255] "" Vector__XXX

BO_ 2415920761 veh_bl_heartbeat: 8 Vector__XXX
 SG_ veh_bl_substate : 56|8@1+ (1,0) [0|255] "" Vector__XXX
 SG_ veh_bl_state : 48|8@1+ (1,0) [0|255] "" Vector__XXX
 SG_ veh_bl_oem_patch : 40|8@1+ (1,0) [0|255] "" Vector__XXX
 SG_ veh_bl_fw_version_bugfix : 32|8@1+ (1,0) [0|255] "" Vector__XXX
 SG_ veh_bl_fw_version_minor : 24|8@1+ (1,0) [0|255] "" Vector__XXX
 SG_ veh_bl_fw_version_major : 16|8@1+ (1,0) [0|255] "" Vector__XXX
 SG_ veh_bl_oem_variant : 8|8@1+ (1,0) [0|255] "" Vector__XXX
 SG_ veh_bl_oem_lookup : 0|8@1+ (1,0) [0|255] "" Vector__XXX

CM_ SG_ 2415920894 fw_homo_patch "Homolgation patch version";
CM_ SG_ 2415920894 fw_homo_minor "Homolgation minor version";
CM_ SG_ 2415920894 fw_homo_major "Homologation major version";
CM_ SG_ 2415920894 fw_dvp_patch "Firmware patch version for the development process";
CM_ SG_ 2415920894 pack_variant "Identifies the pack variant type";
CM_ SG_ 2415920894 hw_minor "Hardware minor version";
CM_ SG_ 2415920894 hw_major "Hardware major version";
CM_ SG_ 2415920894 fw_oem_variant "Specifies the variant of the OEM";
CM_ SG_ 2415920894 fw_oem_lookup "Indicates the OEM lookup index";
CM_ SG_ 2415920895 fw_oem_patch "OEM patch version of the firmware";
CM_ SG_ 2415920895 fw_patch "Patch version of the firmware";
CM_ SG_ 2415920895 fw_minor "Minor version of the firmware";
CM_ SG_ 2415920895 fw_major "Major version of the firmware";
CM_ SG_ 2415920772 reset_counter_value "Value of Reset Counter Value";
CM_ SG_ 2415920772 eeprom_data_state "States of EEPROM Statemachine";
CM_ SG_ 2415920772 mem_tder "Temperature deration value stored in EEPROM";
CM_ SG_ 2415920772 station_soc "SOC value from the station";
CM_ SG_ 2415920772 station_tder "Temperature deration value from the station";
CM_ SG_ 2415920772 station_convergence_cmd "Command from station for SOC convergence";
CM_ SG_ 2415920771 ci_hw_version_minor "CMS Hardware minor version";
CM_ SG_ 2415920771 ci_hw_version_major "CMS Hardware major version";
CM_ SG_ 2415920771 ci_fw_version_patch "Patch version of the CMS firmware";
CM_ SG_ 2415920771 ci_fw_version_minor "Minor version of the CMS firmware";
CM_ SG_ 2415920771 ci_fw_version_major "Major version of the CMS firmware";
CM_ SG_ 2415920771 bms_fw_version_exp "BMS Firmware Version";
CM_ SG_ 2415920771 ci_unique_id "Unique identifier of CMS";
CM_ SG_ 2415920770 bms_hw_version_exp "Hardware version of the BMS";
CM_ SG_ 2415920770 hardware_version_bms "Hardware version of the BMS";
CM_ SG_ 2415920770 adc_current_mcu "ADC value of Current Sensor ";
CM_ SG_ 2415920770 firmware_version_bms "BMS Firmware Version";
CM_ SG_ 2415920769 bms_unique_key "Unique identifier for the BMS";
CM_ SG_ 2415920736 pcb_temperature "Measured PCB temperature in degrees Celsius";
CM_ SG_ 2415920736 afe_itmp "Internal temperature of the AFE in degrees Celsius";
CM_ SG_ 2415920736 soc_from_memory "Stored SOC value retrieved from EEPROM";
CM_ SG_ 2415920736 soc_actual "Actual state of charge (SOC) of the battery in percentage";
CM_ SG_ 2415920646 max_temp_index "Index of the temperature sensor with the highest temperature";
CM_ SG_ 2415920646 min_temp_index "Index of the temperature sensor with the lowest temperature";
CM_ SG_ 2415920646 max_voltage_index "Index of the cell with the highest voltage";
CM_ SG_ 2415920646 min_voltage_index "Index of the cell with the lowest voltage";
CM_ SG_ 2415920647 reset_cause "Cause of the last system reset";
CM_ SG_ 2415920647 characterization_cycle_count "Number of characterization cycles performed";
CM_ SG_ 2415920647 idp_bms_hist "Illegal discharging protection history";
CM_ SG_ 2415920647 rm_bms_hist "Reserve Mode protection history";
CM_ SG_ 2415920647 doc1_bms_hist "Discharge overcurrent 1 protection history";
CM_ SG_ 2415920647 cnot_bms_hist "Connector Over Temperature protection history";
CM_ SG_ 2415920647 afe_tp_bms_hist "AFE Thermal propogation protection history";
CM_ SG_ 2415920647 ib1_bms_hist "Imbalance 1 protection history";
CM_ SG_ 2415920647 ccov_bms_hist "Critical Cell overvoltage protection history";
CM_ SG_ 2415920647 sc_coc1_bms_hist "Slow charge overcurrent 1 protection history";
CM_ SG_ 2415920647 ccuv_bms_hist "Critical Cell undervoltage protection history";
CM_ SG_ 2415920647 icp_hist "Illegal charging protection history";
CM_ SG_ 2415920647 sc_coc_bms_hist "Slow charge overcurrent protection history";
CM_ SG_ 2415920647 roc_bms_hist "Regen Over current protection history";
CM_ SG_ 2415920647 scf_bms_hist "SPI Communication Failure protection history";
CM_ SG_ 2415920647 tso_bms_hist "Temperature sensor open protection history";
CM_ SG_ 2415920647 ib_bms_hist "Imbalance protection history";
CM_ SG_ 2415920647 cso_bms_hist "Current Sensor open protection history";
CM_ SG_ 2415920647 dut_bms_hist "Discharge under-temperature protection history";
CM_ SG_ 2415920647 cut_bms_hist "Charge under-temperature protection history";
CM_ SG_ 2415920647 dot_bms_hist "Discharge over-temperature protection history";
CM_ SG_ 2415920647 cot_bms_hist "Charge over-temperature protection history";
CM_ SG_ 2415920647 doc_bms_hist "Discharge overcurrent protection history";
CM_ SG_ 2415920647 coc_bms_hist "Charge overcurrent protection history";
CM_ SG_ 2415920647 puv_bms_hist "Pack undervoltage protection history";
CM_ SG_ 2415920647 pov_bms_hist "Pack overvoltage protection history";
CM_ SG_ 2415920647 cuv_bms_hist "Undervoltage protection history";
CM_ SG_ 2415920647 cov_bms_hist "Overvoltage protection history";
CM_ SG_ 2415920768 battery_unique_key "Unique identifier for the battery";
CM_ SG_ 2415920642 soh_bms "State of health (SOH) of the battery";
CM_ SG_ 2415920642 cell_balancing_status_bms "Status of cell balancing";
CM_ SG_ 2415920642 sop_bms "State of power (SOP) of the battery";
CM_ SG_ 2415920642 soc_user "State of charge (SOC) for the user";
CM_ SG_ 2415920641 idp_flag_bms "Illegal discharging protection flag";
CM_ SG_ 2415920641 rm_flag_bms "Reserve mode protection flag";
CM_ SG_ 2415920641 doc1_flag_bms "Discharge overcurrent 1 protection flag";
CM_ SG_ 2415920641 cnot_flag_bms "Connector over temperature protection flag";
CM_ SG_ 2415920641 afe_tp_bms_flag "AFE thermal propagation protection flag";
CM_ SG_ 2415920641 ib1_bms_flag "Imbalance 1 protection flag";
CM_ SG_ 2415920641 ccov_flag_bms "Critical cell overvoltage protection flag";
CM_ SG_ 2415920641 sc_coc1_flag_bms "Slow charge overcurrent 1 protection flag";
CM_ SG_ 2415920641 ccuv_flag_bms "Critical cell undervoltage protection flag";
CM_ SG_ 2415920641 icp_flag "Illegal charging protection flag";
CM_ SG_ 2415920641 sc_coc_flag_bms "Slow charge overcurrent protection flag";
CM_ SG_ 2415920641 roc_flag_bms "Regen overcurrent protection flag";
CM_ SG_ 2415920641 scf_flag_bms "SPI communication failure protection flag";
CM_ SG_ 2415920641 tso_flag_bms "Temperature sensor open protection flag";
CM_ SG_ 2415920641 ib_bms_flag "Imbalance protection flag";
CM_ SG_ 2415920641 cso_flag_bms "Current sensor open protection flag";
CM_ SG_ 2415920641 dut_flag_bms "Discharge under-temperature protection flag";
CM_ SG_ 2415920641 cut_flag_bms "Charge under-temperature protection flag";
CM_ SG_ 2415920641 dot_flag_bms "Discharge over-temperature protection flag";
CM_ SG_ 2415920641 cot_flag_bms "Charge over-temperature protection flag";
CM_ SG_ 2415920641 doc_flag_bms "Discharge overcurrent protection flag";
CM_ SG_ 2415920641 coc_flag_bms "Charge overcurrent protection flag";
CM_ SG_ 2415920641 puv_flag_bms "Pack undervoltage protection flag";
CM_ SG_ 2415920641 pov_flag_bms "Pack overvoltage protection flag";
CM_ SG_ 2415920641 cuv_flag_bms "Undervoltage protection flag";
CM_ SG_ 2415920641 cov_flag_bms "Overvoltage protection flag";
CM_ SG_ 2415920641 idp_bms "Illegal discharging protection status";
CM_ SG_ 2415920641 rm_bms "Reserve mode protection status";
CM_ SG_ 2415920641 doc1_bms "Discharge overcurrent 1 protection status";
CM_ SG_ 2415920641 cnot_bms "Connector over temperature protection status";
CM_ SG_ 2415920641 afe_tp_bms "AFE thermal propagation protection status";
CM_ SG_ 2415920641 ib1_bms "Imbalance 1 protection status";
CM_ SG_ 2415920641 ccov_bms "Critical cell overvoltage protection status";
CM_ SG_ 2415920641 sc_coc1_bms "Slow charge overcurrent 1 protection status";
CM_ SG_ 2415920641 ccuv_bms "Critical cell undervoltage protection status";
CM_ SG_ 2415920641 icp_status "Illegal charging protection status";
CM_ SG_ 2415920641 sc_coc_bms "Slow charge overcurrent protection status";
CM_ SG_ 2415920641 roc_bms "Regen overcurrent protection status";
CM_ SG_ 2415920641 scf_bms "SPI communication failure protection status";
CM_ SG_ 2415920641 tso_bms "Temperature sensor open protection status";
CM_ SG_ 2415920641 ib_bms "Imbalance protection status";
CM_ SG_ 2415920641 cso_bms "Current sensor open protection status";
CM_ SG_ 2415920641 dut_bms "Discharge under-temperature protection status";
CM_ SG_ 2415920641 cut_bms "Charge under-temperature protection status";
CM_ SG_ 2415920641 dot_bms "Discharge over-temperature protection status";
CM_ SG_ 2415920641 cot_bms "Charge over-temperature protection status";
CM_ SG_ 2415920641 doc_bms "Discharge overcurrent protection status";
CM_ SG_ 2415920641 coc_bms "Charge overcurrent protection status";
CM_ SG_ 2415920641 puv_bms "Pack undervoltage protection status";
CM_ SG_ 2415920641 pov_bms "Pack overvoltage protection status";
CM_ SG_ 2415920641 cuv_bms "Undervoltage protection status";
CM_ SG_ 2415920641 cov_bms "Overvoltage protection status";
CM_ SG_ 2415920688 cell_voltage_4 "Voltage of cell 4 in the battery pack";
CM_ SG_ 2415920688 cell_voltage_3 "Voltage of cell 3 in the battery pack";
CM_ SG_ 2415920688 cell_voltage_2 "Voltage of cell 2 in the battery pack";
CM_ SG_ 2415920688 cell_voltage_1 "Voltage of cell 1 in the battery pack";
CM_ SG_ 2415920689 cell_voltage_8 "Voltage of cell 8 in the battery pack";
CM_ SG_ 2415920689 cell_voltage_7 "Voltage of cell 7 in the battery pack";
CM_ SG_ 2415920689 cell_voltage_6 "Voltage of cell 6 in the battery pack";
CM_ SG_ 2415920689 cell_voltage_5 "Voltage of cell 5 in the battery pack";
CM_ SG_ 2415920690 cell_voltage_12 "Voltage of cell 12 in the battery pack";
CM_ SG_ 2415920690 cell_voltage_11 "Voltage of cell 11 in the battery pack";
CM_ SG_ 2415920690 cell_voltage_10 "Voltage of cell 10 in the battery pack";
CM_ SG_ 2415920690 cell_voltage_9 "Voltage of cell 9 in the battery pack";
CM_ SG_ 2415920691 cell_voltage_16 "Voltage of cell 16 in the battery pack";
CM_ SG_ 2415920691 cell_voltage_15 "Voltage of cell 15 in the battery pack";
CM_ SG_ 2415920691 cell_voltage_14 "Voltage of cell 14 in the battery pack";
CM_ SG_ 2415920691 cell_voltage_13 "Voltage of cell 13 in the battery pack";
CM_ SG_ 2415920644 voltage_imbalance_bms "Voltage imbalance of cells in the battery pack";
CM_ SG_ 2415920644 pack_voltage_bms "Summation of all the cell voltages ";
CM_ SG_ 2415920644 max_cell_voltage_exp "Maximum cell voltage measured in the battery pack";
CM_ SG_ 2415920644 min_cell_voltage_exp "Minimum cell voltage measured in the battery pack";
CM_ SG_ 2415920722 m4_ct3 "Temperature of m4_ct3";
CM_ SG_ 2415920722 m4_ct2 "Temperature of m4_ct2";
CM_ SG_ 2415920722 m4_ct1 "Temperature of m4_ct1";
CM_ SG_ 2415920722 m3_ct3 "Temperature of m3_ct3";
CM_ SG_ 2415920723 busbar_temperature "Temperature of busbar";
CM_ SG_ 2415920723 shunt_resistor_temperature "Temperature of shunt resistor";
CM_ SG_ 2415920723 discharge_contactor_temperature "Temperature of discharge contactor";
CM_ SG_ 2415920723 charge_contactor_temperature "Temperature of charge contactor";
CM_ SG_ 2415920720 m2_ct1 "Temperature of m2_ct1";
CM_ SG_ 2415920720 m1_ct3 "Temperature of m1_ct3";
CM_ SG_ 2415920720 m1_ct2 "Temperature of m1_ct2";
CM_ SG_ 2415920720 m1_ct1 "Temperature of m1_ct1";
CM_ SG_ 2415920721 m3_ct2 "Temperature of m3_ct2";
CM_ SG_ 2415920721 m3_ct1 "Temperature of m3_ct1";
CM_ SG_ 2415920721 m2_ct3 "Temperature of m2_ct3";
CM_ SG_ 2415920721 m2_ct2 "Temperature of m2_ct2";
CM_ SG_ 2415920645 dti_ah "Discrete Time Integrator Ah";
CM_ SG_ 2415920645 temp_imbalance_bms "Temperature imbalance in the battery pack";
CM_ SG_ 2415920645 max_cell_temp_exp "Maximum cell temperature measured in the battery pack";
CM_ SG_ 2415920645 min_cell_temp_exp "Minimum cell temperature measured in the battery pack";
CM_ SG_ 2415920643 charge_cycle_count_bms "Number of Charging Cycles of BMS";
CM_ SG_ 2415920643 last_discharge_ah_bms "Last Discharge Ah of BMS";
CM_ SG_ 2415920643 last_charge_ah_bms "Last Charge Ah of BMS";
CM_ SG_ 2415920643 bms_current_exp "Current Value of BMS";
CM_ SG_ 2415920640 gun_unlock_retry_count "Gun unlock retry count";
CM_ SG_ 2415920640 gun_lock_retry_count "Gun lock retry count";
CM_ SG_ 2415920640 solenoid_feedback "Solenoid feedback flag";
CM_ SG_ 2415920640 gun_lock_req "Gun lock request flag";
CM_ SG_ 2415920640 gun_unlock_failed "Gun unlock failure flag";
CM_ SG_ 2415920640 gun_unlock_status "Gun unlock status flag";
CM_ SG_ 2415920640 gun_lock_failed "Gun lock failure flag";
CM_ SG_ 2415920640 gun_lock_status "Gun lock status flag";
CM_ SG_ 2415920640 cc_on_req "Charge Contactor on request flag";
CM_ SG_ 2415920640 motor_enable_out_bms "Motor enable output flag";
CM_ SG_ 2415920640 discharge_contactor_out_bms "Discharge contactor output flag";
CM_ SG_ 2415920640 discharge_precharge_out_bms "Discharge precharge output flag";
CM_ SG_ 2415920640 charge_contactor_out_bms "Charge contactor output flag";
CM_ SG_ 2415920640 charge_precharge_out_bms "Charge precharge output flag";
CM_ SG_ 2415920640 proximity_pilot_in_bms "Proximity pilot in flag";
CM_ SG_ 2415920640 key_in_bms "Key-in status flag";
CM_ SG_ 2415920640 shutdown_flag_3 "Shutdown flag 3";
CM_ SG_ 2415920640 shutdown_flag_2 "Shutdown flag 2";
CM_ SG_ 2415920640 shutdown_flag_1 "Shutdown flag 1";
CM_ SG_ 2415920640 battery_state_bms "State of Battery";
CM_ SG_ 2415920640 dut_warning "Discharge under temperature warning";
CM_ SG_ 2415920640 tp_warning "Thermal Propogation warning";
CM_ SG_ 2415920640 dot_warning "Discharge over temperature warning";
CM_ SG_ 2415920640 tp_alarm_exp "Thermal Propogation alarm flag";
CM_ SG_ 2415920640 charge_complete_status "Charge complete status flag";
CM_ SG_ 2415920640 fast_charger_detected_bms "Fast charger detected flag";
CM_ SG_ 2415920640 slow_charger_detected_bms "Slow charger detected flag";
CM_ SG_ 2415920640 discharge_path_status_bms "Discharge path status flag";
CM_ SG_ 2415920640 charge_path_status_bms "Charge path status flag";
CM_ SG_ 2415920640 discharge_pf_ok_bms "Ok to Discharge Protection Flag";
CM_ SG_ 2415920640 charge_pf_ok_bms "Ok to Charge Protection Flag";
CM_ SG_ 2415920640 discharge_io_ok_bms "Ok to Discharge I/O flag";
CM_ SG_ 2415920640 charge_io_ok_bms "Ok to Charge I/O flag";
CM_ SG_ 2415920640 discharge_protection_ok_bms "Ok to Discharge Protection Status";
CM_ SG_ 2415920640 charge_protection_ok_bms "Ok to Charge Protection Status";
CM_ SG_ 2415920773 bms_dc_mainstate "Discharge Contactor Mainstate";
CM_ SG_ 2415920773 bms_dc_bus_voltage "DC Bus Voltage";
CM_ SG_ 2415920773 odo_low "Low byte of odometer reading";
CM_ SG_ 2415920773 odo_high "High byte of odometer reading";
CM_ SG_ 2415920737 bms_charge_cycle_count_increment "BMS charge cycle count increment value";
CM_ SG_ 2415920737 bms_actual_ah "BMS actual Ah value";
CM_ SG_ 2415920737 bms_pack_ah "BMS pack Ah value";
CM_ SG_ 2415920737 bms_dti_start_ah "BMS DTI start Ah value";
CM_ SG_ 2415920738 bms_afe_adc_filtered "Filtered ADC value of Current Sensor";
CM_ SG_ 2415920738 bms_mem_cs_gain "Current Sensor Gain Value in EEPROM";
CM_ SG_ 2415920738 bms_tder "Temperature derating (TDER) value in the BMS";
CM_ SG_ 2415920738 bms_substate "Substate of the BMS";
CM_ SG_ 2415920738 bms_solenoid_mainstate "Solenoid main state of the BMS";
CM_ SG_ 2415920738 bms_slow_charge_mainstate "Slow charge main state of the BMS";
CM_ SG_ 2415920738 bms_thermistor_type "Thermistor type used in the BMS";
CM_ SG_ 2415920738 bms_mainstate "Main state of the BMS";
CM_ SG_ 2415920739 bms_mem_chtz_count "Characterization Cycle Count Value in EEPROM";
CM_ SG_ 2415920739 bms_mem_cycle_count "Cycle Count Value in EEPROM";
CM_ SG_ 2415920739 bms_mem_tbeta "Temperature Sensor Beta Value";
CM_ SG_ 2415920739 bms_mem_cs_offset "Current Sensor offset value in EEPROM";
CM_ SG_ 2415920893 bms_app_bl_oem_patch "Bootloader OEM patch version";
CM_ SG_ 2415920893 bms_app_bl_fw_version_bugfix "Bootloader firmware version bugfix";
CM_ SG_ 2415920893 bms_app_bl_fw_version_minor "Bootloader firmware version minor";
CM_ SG_ 2415920893 bms_app_bl_fw_version_major "Bootloader firmware version major";
CM_ SG_ 2415920893 bms_app_bl_oem_variant "Bootloader OEM variant value";
CM_ SG_ 2415920893 bms_app_bl_oem_lookup "Bootloader OEM lookup value";
CM_ SG_ 2415920740 bms_kwh_capacity "KwH capacity of Battery";
CM_ SG_ 2415920740 bms_soh_days "SoH (State of Health) days";
CM_ SG_ 2415920740 bms_soh_calage "SoH calender age value";
CM_ SG_ 2415920740 bms_live_cs_offset "Live current sensor offset value";
CM_ SG_ 2415920741 bms_pack_nominal_voltage "Nominal Pack Voltage of Battery";
CM_ SG_ 2415920741 bms_default_capacity "Default Capacity of Battery";
CM_ SG_ 2415920741 bms_dod "Depth of Discharge of Battery";
CM_ SG_ 2415920741 bms_cnt_max_cell_temp_exp "Connector Max cell temperature";
CM_ SG_ 2415920741 bms_cnt_min_cell_temp_exp "Connector Min cell temperature";
CM_ SG_ 2415920848 bb_hb_byte7 "Heartbeat byte 7";
CM_ SG_ 2415920848 bb_hb_byte6 "Heartbeat byte 6";
CM_ SG_ 2415920848 bb_hb_byte5 "Heartbeat byte 5";
CM_ SG_ 2415920848 bb_hb_byte4 "Heartbeat byte 4";
CM_ SG_ 2415920848 bb_hb_byte3 "Heartbeat byte 3";
CM_ SG_ 2415920848 bb_hb_byte2 "Heartbeat byte 2";
CM_ SG_ 2415920848 bb_hb_byte1 "Heartbeat byte 1";
CM_ SG_ 2415920848 bb_hb_byte0 "Heartbeat byte 0 ";
CM_ SG_ 2415920864 cloud_unique_id "Cloud immobilisation unique id";
CM_ SG_ 2415920864 cloud_special_level "Cloud immobilisation special level";
CM_ SG_ 2415920864 cloud_onboard_cmd "Cloud immobilisation onboard command";
CM_ SG_ 2415920865 cloud_immb_level "Cloud immobilisation level";
CM_ SG_ 2415920865 cloud_immb_cmd "Cloud immobilisation command";
CM_ SG_ 2415920880 bms_immb_fw_compatibilty "BMS immobilisation firmware compatibility";
CM_ SG_ 2415920880 bms_immb_status "BMS immobilisation status ";
CM_ SG_ 2415920880 bms_immb_substate "BMS immobilisation substate";
CM_ SG_ 2415920880 bms_immb_mainstate "BMS immobilisation main state";
CM_ SG_ 2415920880 bms_immb_level "BMS immobilisation level acknowledgment";
CM_ SG_ 2415920880 bms_immb_cmd_status "BMS immobilisation command status";
CM_ SG_ 2415920880 bms_immb_health_status "BMS immobilisation health status";
CM_ SG_ 2415920880 bms_immb_source "BMS immobilisation source";
CM_ SG_ 2415920880 bms_immb_onboard_status "BMS immobilisation onboard status";
